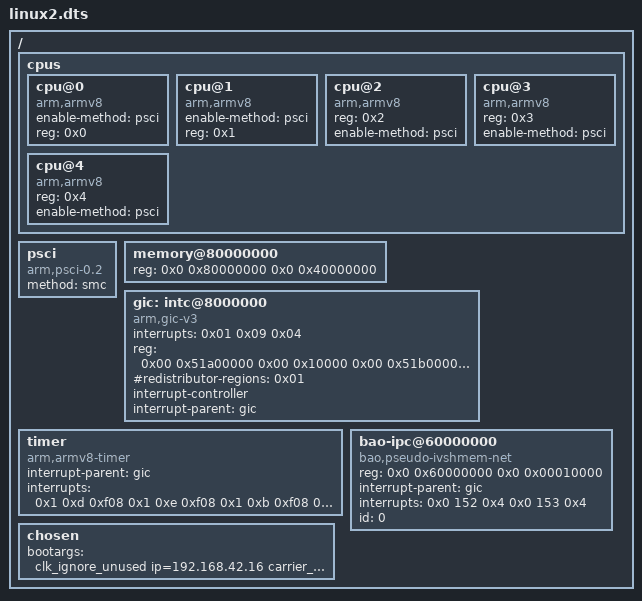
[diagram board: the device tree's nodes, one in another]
/dts-v1/;

/ {   
	#size-cells = <0x2>;
	#address-cells = <0x2>;

	cpus {
		#size-cells = <0x0>;
		#address-cells = <0x1>;

		cpu@0 {
			compatible = "arm,armv8";
			device_type = "cpu";
			enable-method = "psci";
			reg = <0x0>;
		};

		cpu@1 {
			compatible = "arm,armv8";
			device_type = "cpu";
			enable-method = "psci";
			reg = <0x1>;
		};

		cpu@2 {
			reg = <0x2>;
			compatible = "arm,armv8";
			device_type = "cpu";
			enable-method = "psci";
		};

		cpu@3 {
			reg = <0x3>;
			compatible = "arm,armv8";
			device_type = "cpu";
			enable-method = "psci";
		};

		cpu@4 {
			compatible = "arm,armv8";
			device_type = "cpu";
			reg = <0x4>;
			enable-method = "psci";
		};

	};

	psci {
		compatible = "arm,psci-0.2";
		method = "smc";
	};


	memory@80000000 {
		reg = <0x0 0x80000000 0x0 0x40000000>;
		device_type = "memory";
	};

	gic: intc@8000000 {
		interrupts = <0x01 0x09 0x04>;
		reg = <0x00 0x51a00000 0x00 0x10000 0x00 0x51b00000 0x00 0xf60000>;
		#redistributor-regions = <0x01>;
		compatible = "arm,gic-v3";
		interrupt-controller;
		#interrupt-cells = <0x03>;
        interrupt-parent = <&gic>;
	};

   	timer {
		compatible = "arm,armv8-timer";
		interrupt-parent = <&gic>;
		interrupts = <0x1 0xd 0xf08 0x1 0xe 0xf08 0x1 0xb 0xf08 0x1 0xa 0xf08>;
	};

    bao-ipc@60000000 {
        compatible = "bao,pseudo-ivshmem-net";
        #address-cells = <2>;
        #size-cells = <2>;
        reg = <0x0 0x60000000 0x0 0x00010000>;
        interrupt-parent = <&gic>;
        interrupts = <0x0 152 0x4 0x0 153 0x4>;
        id = <0>;
    };

	chosen {
		bootargs = "clk_ignore_unused ip=192.168.42.16 carrier_timeout=0";
	};
};
